# cpsw_CPSW3_08000000h register map
Vendor: Texas Instruments
Registers are 32-bit, read-write, reset 0x0 unless marked. A register's access mark holds for its fields unless they carry their own. Offsets are as the file gives them; [hi:lo] are bit positions; {n}, {i} and the like mark numbered series; 'fields as' and 'values as' point back to an identical list.

## cpsw3 (part 3 of 3)
0x22048 cpsw3_CPSW_NU_CPSW_NU_ETH_MAC_0_PN_IET_VERIFY_REG reset 0x1312D0 — Enet Port N IET VERIFY
  [23:0] MAC_VERIFY_CNT — IET MAC VERIFY COUNT
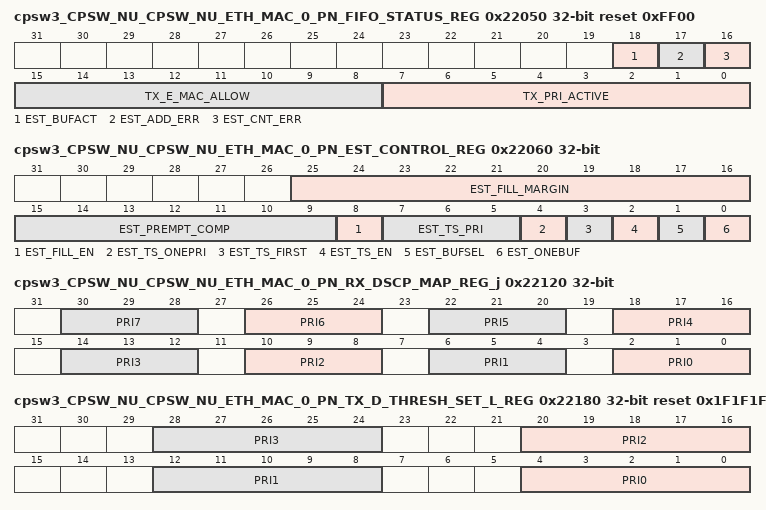
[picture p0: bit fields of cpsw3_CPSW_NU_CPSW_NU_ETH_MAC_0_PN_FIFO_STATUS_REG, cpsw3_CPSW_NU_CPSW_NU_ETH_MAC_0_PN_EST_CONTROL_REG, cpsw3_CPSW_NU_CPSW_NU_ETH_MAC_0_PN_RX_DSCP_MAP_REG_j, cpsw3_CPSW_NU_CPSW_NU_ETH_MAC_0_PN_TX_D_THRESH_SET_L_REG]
0x22050 cpsw3_CPSW_NU_CPSW_NU_ETH_MAC_0_PN_FIFO_STATUS_REG ro reset 0xFF00 — Enet Port N FIFO STATUS
  [18] EST_BUFACT — Transmit FIFO EST Buffer Active
  [17] EST_ADD_ERR — Transmit FIFO EST Address Error
  [16] EST_CNT_ERR — Transmit FIFO EST Count Error
  [15:8] TX_E_MAC_ALLOW — Transmit FIFO Express Queue Priority Allow
  [7:0] TX_PRI_ACTIVE — Transmit FIFO Priority Active
0x22060 cpsw3_CPSW_NU_CPSW_NU_ETH_MAC_0_PN_EST_CONTROL_REG — Enet Port N EST CONTROL
  [25:16] EST_FILL_MARGIN — Transmit FIFO EST Fill Margin
  [15:9] EST_PREMPT_COMP — Transmit FIFO EST Prempt Comparison Value to Clear wire
  [8] EST_FILL_EN — Transmit FIFO EST Fill Enable
  [7:5] EST_TS_PRI — Transmit FIFO EST TimeStamp Priority
  [4] EST_TS_ONEPRI — Transmit FIFO EST TimeStamp One Priority
  [3] EST_TS_FIRST — Transmit FIFO EST TimeStamp First Express Packet
  [2] EST_TS_EN — Transmit FIFO EST TimeStamp Enable
  [1] EST_BUFSEL — Transmit FIFO EST Buffer Select
  [0] EST_ONEBUF — Transmit FIFO EST One Buffer
0x22120 cpsw3_CPSW_NU_CPSW_NU_ETH_MAC_0_PN_RX_DSCP_MAP_REG_j — Enet Port N Receive IPV4/IPV6 DSCP Map M
  [4n+2:4n] PRI{n} (n=0..7) — A DSCP IPV4/V6 packet TOS of N*8+{n} is mapped to this received priority
0x22140 cpsw3_CPSW_NU_CPSW_NU_ETH_MAC_0_PN_PRI_CIR_REG_j — Enet Port N Rx Priority P Committed Information Rate Value
  [27:0] PRI_CIR — Priority N committed information rate
0x22160 cpsw3_CPSW_NU_CPSW_NU_ETH_MAC_0_PN_PRI_EIR_REG_j — Enet Port N Rx Priority P Excess Informatoin Rate Value
  [27:0] PRI_EIR — Priority N Excess Information Rate count
0x22180 cpsw3_CPSW_NU_CPSW_NU_ETH_MAC_0_PN_TX_D_THRESH_SET_L_REG reset 0x1F1F1F1F — Enet Port N Tx PFC Destination Threshold Set Low
  [8n+4:8n] PRI{n} (n=0..3) — Port Priority Based Flow Control Threshold Set Value for Priority {n}
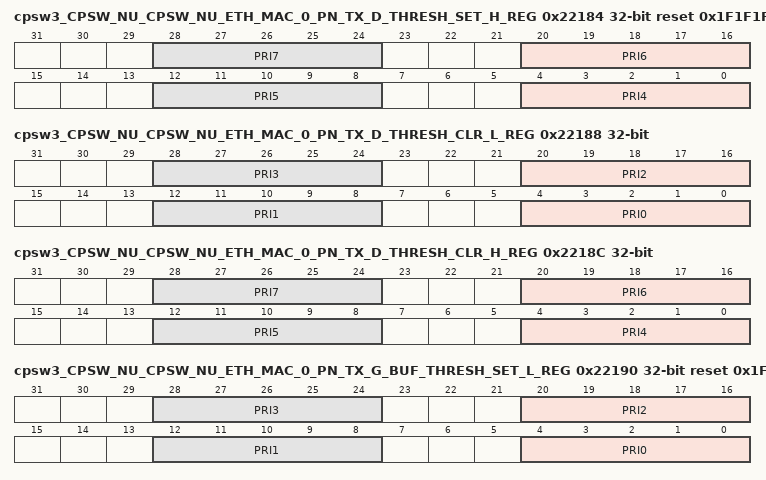
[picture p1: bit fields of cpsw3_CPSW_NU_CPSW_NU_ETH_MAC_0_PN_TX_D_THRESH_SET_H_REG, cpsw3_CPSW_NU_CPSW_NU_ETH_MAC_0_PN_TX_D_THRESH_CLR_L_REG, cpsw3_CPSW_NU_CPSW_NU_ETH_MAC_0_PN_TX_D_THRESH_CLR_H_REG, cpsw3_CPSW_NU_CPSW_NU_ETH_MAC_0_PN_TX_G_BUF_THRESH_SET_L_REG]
0x22184 cpsw3_CPSW_NU_CPSW_NU_ETH_MAC_0_PN_TX_D_THRESH_SET_H_REG reset 0x1F1F1F1F — Enet Port N Tx PFC Destination Threshold Set High
  [8n-28:8n-32] PRI{n} (n=4..7) — Port Priority Based Flow Control Threshold Set Value for Priority {n}
0x22188 cpsw3_CPSW_NU_CPSW_NU_ETH_MAC_0_PN_TX_D_THRESH_CLR_L_REG — Enet Port N Tx PFC Destination Threshold Clr Low
  [8n+4:8n] PRI{n} (n=0..3) — Port Priority Based Flow Control Threshold Clear Value for Priority {n}
0x2218C cpsw3_CPSW_NU_CPSW_NU_ETH_MAC_0_PN_TX_D_THRESH_CLR_H_REG — Enet Port N Tx PFC Destination Threshold Clr High
  [8n-28:8n-32] PRI{n} (n=4..7) — Port Priority Based Flow Control Threshold Clear Value for Priority {n}
0x22190 cpsw3_CPSW_NU_CPSW_NU_ETH_MAC_0_PN_TX_G_BUF_THRESH_SET_L_REG reset 0x1F1F1F1F — Enet Port N Tx PFC Global Buffer Threshold Set Low
  fields as cpsw3_CPSW_NU_CPSW_NU_ETH_MAC_0_PN_TX_D_THRESH_SET_L_REG
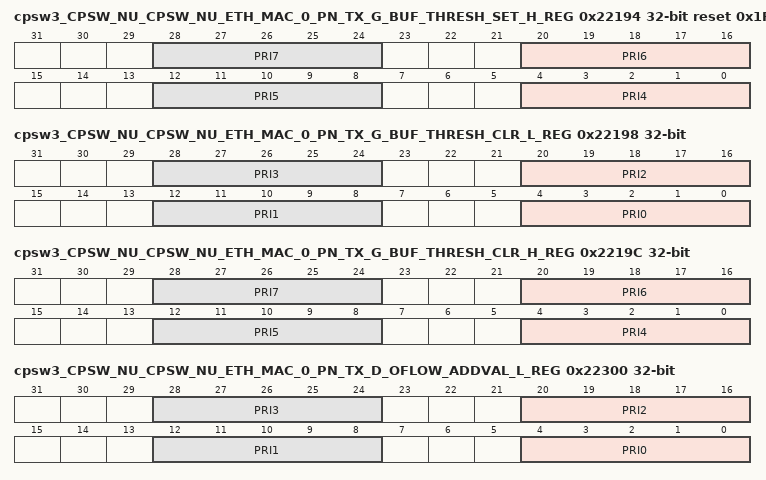
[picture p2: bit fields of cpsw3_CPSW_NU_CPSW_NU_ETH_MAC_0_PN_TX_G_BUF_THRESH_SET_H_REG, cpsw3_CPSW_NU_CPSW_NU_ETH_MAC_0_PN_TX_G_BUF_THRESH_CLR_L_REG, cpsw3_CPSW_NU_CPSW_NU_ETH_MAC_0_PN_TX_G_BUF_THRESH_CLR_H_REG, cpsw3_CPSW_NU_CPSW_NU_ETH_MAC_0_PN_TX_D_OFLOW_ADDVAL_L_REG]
0x22194 cpsw3_CPSW_NU_CPSW_NU_ETH_MAC_0_PN_TX_G_BUF_THRESH_SET_H_REG reset 0x1F1F1F1F — Enet Port N Tx PFC Global Buffer Threshold Set High
  fields as cpsw3_CPSW_NU_CPSW_NU_ETH_MAC_0_PN_TX_D_THRESH_SET_H_REG
0x22198 cpsw3_CPSW_NU_CPSW_NU_ETH_MAC_0_PN_TX_G_BUF_THRESH_CLR_L_REG — Enet Port N Tx PFC Global Buffer Threshold Clr Low
  fields as cpsw3_CPSW_NU_CPSW_NU_ETH_MAC_0_PN_TX_D_THRESH_CLR_L_REG
0x2219C cpsw3_CPSW_NU_CPSW_NU_ETH_MAC_0_PN_TX_G_BUF_THRESH_CLR_H_REG — Enet Port N Tx PFC Global Buffer Threshold Clr High
  fields as cpsw3_CPSW_NU_CPSW_NU_ETH_MAC_0_PN_TX_D_THRESH_CLR_H_REG
0x22300 cpsw3_CPSW_NU_CPSW_NU_ETH_MAC_0_PN_TX_D_OFLOW_ADDVAL_L_REG — Enet Port N Tx Destination Out Flow Add Values Low
  [8n+4:8n] PRI{n} (n=0..3) — Port PFC Destination Based Out Flow Add Value for Priority {n}
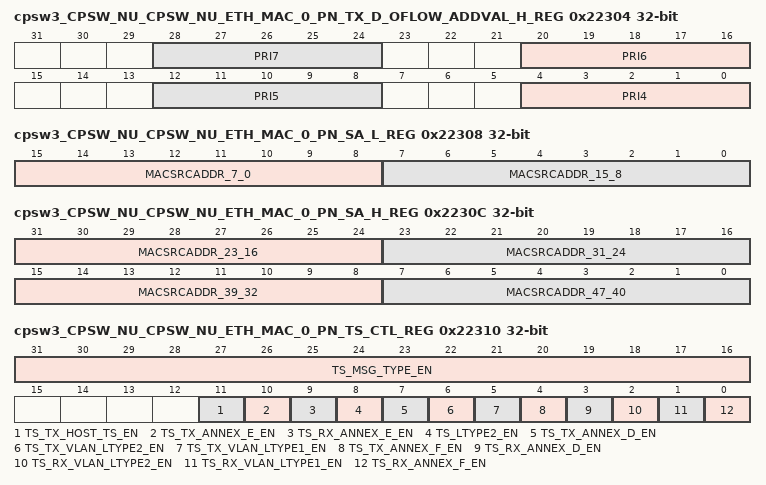
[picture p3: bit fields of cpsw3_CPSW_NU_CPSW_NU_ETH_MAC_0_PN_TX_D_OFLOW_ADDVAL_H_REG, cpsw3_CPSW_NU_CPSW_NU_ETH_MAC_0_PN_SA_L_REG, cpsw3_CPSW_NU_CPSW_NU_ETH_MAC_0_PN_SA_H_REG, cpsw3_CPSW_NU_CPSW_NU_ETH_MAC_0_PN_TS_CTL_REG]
0x22304 cpsw3_CPSW_NU_CPSW_NU_ETH_MAC_0_PN_TX_D_OFLOW_ADDVAL_H_REG — Enet Port N Tx Destination Out Flow Add Values High
  [8n-28:8n-32] PRI{n} (n=4..7) — Port PFC Destination Based Out Flow Add Value for Priority {n}
0x22308 cpsw3_CPSW_NU_CPSW_NU_ETH_MAC_0_PN_SA_L_REG — Enet Port N Tx Pause Frame Source Address Low
  [15:8] MACSRCADDR_7_0 — Source Address Lower 8 bits
  [7:0] MACSRCADDR_15_8 — Source Address bits 15:8
0x2230C cpsw3_CPSW_NU_CPSW_NU_ETH_MAC_0_PN_SA_H_REG — Enet Port N Tx Pause Frame Source Address High
  [31:24] MACSRCADDR_23_16 — Source Address bits 23:16
  [23:16] MACSRCADDR_31_24 — Source Address bits 31:24
  [15:8] MACSRCADDR_39_32 — Source Address bits 39:32
  [7:0] MACSRCADDR_47_40 — Source Address bits 47:40
0x22310 cpsw3_CPSW_NU_CPSW_NU_ETH_MAC_0_PN_TS_CTL_REG — Enet Port N Time Sync Control
  [31:16] TS_MSG_TYPE_EN — Time Sync Message Type Enable
  [11] TS_TX_HOST_TS_EN — Time Sync Transmit Host Time Stamp Enable
  [10] TS_TX_ANNEX_E_EN — Time Synce Transmit Annex E Enable
  [9] TS_RX_ANNEX_E_EN — Time Synce Receive Annex E Enable
  [8] TS_LTYPE2_EN — Time Sync LTYPE 2 enable transmit and receive
  [7] TS_TX_ANNEX_D_EN — Time Synce Transmit Annex D Enable
  [6] TS_TX_VLAN_LTYPE2_EN — Time Sync Transmit VLAN LTYPE 2 enable
  [5] TS_TX_VLAN_LTYPE1_EN — Time Sync Transmit VLAN LTYPE 1 enable
  [4] TS_TX_ANNEX_F_EN — Time Synce Transmit Annex F Enable
  [3] TS_RX_ANNEX_D_EN — Time Synce Receive Annex D Enable
  [2] TS_RX_VLAN_LTYPE2_EN — Time Sync Receive VLAN LTYPE 2 enable
  [1] TS_RX_VLAN_LTYPE1_EN — Time Sync Receive VLAN LTYPE 1 enable
  [0] TS_RX_ANNEX_F_EN — Time Synce Receive Annex F Enable
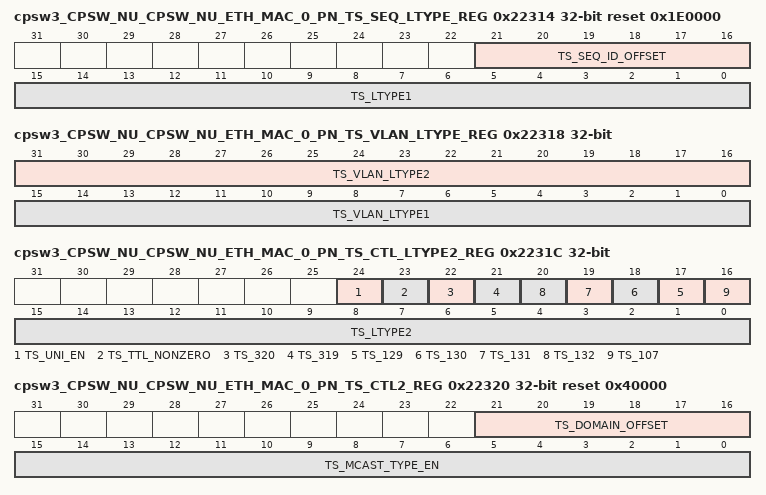
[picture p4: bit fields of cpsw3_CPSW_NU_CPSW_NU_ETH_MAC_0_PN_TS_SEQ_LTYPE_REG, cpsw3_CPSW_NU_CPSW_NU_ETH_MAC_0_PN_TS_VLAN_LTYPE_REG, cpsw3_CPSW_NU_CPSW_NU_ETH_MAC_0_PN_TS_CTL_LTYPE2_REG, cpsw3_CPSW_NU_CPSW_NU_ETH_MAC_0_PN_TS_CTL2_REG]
0x22314 cpsw3_CPSW_NU_CPSW_NU_ETH_MAC_0_PN_TS_SEQ_LTYPE_REG reset 0x1E0000 — Enet Port N Time Sync LTYPE (and SEQ_ID_OFFSET)
  [21:16] TS_SEQ_ID_OFFSET — Time Sync Sequence ID Offset
  [15:0] TS_LTYPE1 — Time Sync LTYPE1
0x22318 cpsw3_CPSW_NU_CPSW_NU_ETH_MAC_0_PN_TS_VLAN_LTYPE_REG — Enet Port N Time Sync VLAN2 and VLAN2
  [31:16] TS_VLAN_LTYPE2 — Time Sync VLAN LTYPE2
  [15:0] TS_VLAN_LTYPE1 — Time Sync VLAN LTYPE1
0x2231C cpsw3_CPSW_NU_CPSW_NU_ETH_MAC_0_PN_TS_CTL_LTYPE2_REG — Enet Port N Time Sync Control and LTYPE 2
  [24] TS_UNI_EN — Time Sync Unicast Enable
  [23] TS_TTL_NONZERO — Time Sync Time to Live Non-zero Enable
  [22] TS_320 — Time Sync Destination IP Address 320 Enable
  [21] TS_319 — Time Sync Destination IP Address 319 Enable
  [n-112] TS_{n} (n=129..132) — Time Sync Destination IP Address {n} Enable
  [16] TS_107 — Time Sync Destination IP Address 107 Enable
  [15:0] TS_LTYPE2 — Time Sync LTYPE2
0x22320 cpsw3_CPSW_NU_CPSW_NU_ETH_MAC_0_PN_TS_CTL2_REG reset 0x40000 — Enet Port N Time Sync Control 2
  [21:16] TS_DOMAIN_OFFSET — Time Sync Domain Offset
  [15:0] TS_MCAST_TYPE_EN — Time Sync Multicast Destination Address Type Enable
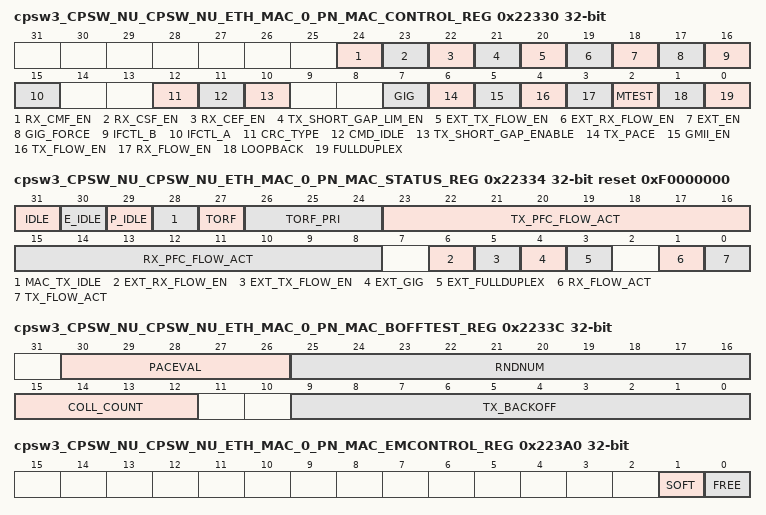
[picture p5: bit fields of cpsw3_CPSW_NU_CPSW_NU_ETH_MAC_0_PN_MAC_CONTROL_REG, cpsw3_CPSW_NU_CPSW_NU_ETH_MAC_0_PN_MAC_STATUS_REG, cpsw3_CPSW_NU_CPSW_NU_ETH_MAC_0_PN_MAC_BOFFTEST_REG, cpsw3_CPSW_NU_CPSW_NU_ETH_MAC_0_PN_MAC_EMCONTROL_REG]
0x22330 cpsw3_CPSW_NU_CPSW_NU_ETH_MAC_0_PN_MAC_CONTROL_REG — Enet Port N Mac Control
  [24] RX_CMF_EN — RX Copy MAC Control Frames Enable
  [23] RX_CSF_EN — RX Copy Short Frames Enable
  [22] RX_CEF_EN — RX Copy Error Frames Enable
  [21] TX_SHORT_GAP_LIM_EN — Transmit Short Gap Limit Enable
  [20] EXT_TX_FLOW_EN — External Transmit Flow Control Enable
  [19] EXT_RX_FLOW_EN — External Receive Flow Control Enable
  [18] EXT_EN — External Enable
  [17] GIG_FORCE — Gigabit Mode Force
  [16] IFCTL_B — Interface Control B
  [15] IFCTL_A — Interface Control A
  [12] CRC_TYPE — Port CRC Type
  [11] CMD_IDLE — Command Idle
  [10] TX_SHORT_GAP_ENABLE — Transmit Short Gap Enable
  [7] GIG — Gigabit Mode
  [6] TX_PACE — Transmit Pacing Enable
  [5] GMII_EN — GMII Enable
  [4] TX_FLOW_EN — Transmit Flow Control Enable
  [3] RX_FLOW_EN — Receive Flow Control Enable
  [2] MTEST — Manufacturing Test Mode
  [1] LOOPBACK — Loop Back Mode
  [0] FULLDUPLEX — Full Duplex mode
0x22334 cpsw3_CPSW_NU_CPSW_NU_ETH_MAC_0_PN_MAC_STATUS_REG ro reset 0xF0000000 — Enet Port N Mac Status
  [31] IDLE — cpxmac_sl IDLE
  [30] E_IDLE — Express cpxmac_sl IDLE
  [29] P_IDLE — Prempt cpxmac_sl IDLE
  [28] MAC_TX_IDLE — Prempt and Express cpxmac_sl Transmit IDLE
  [27] TORF — Top of receive FIFO flow control trigger occurred. This bit is write one to clear.
  [26:24] TORF_PRI — The lowest priority that caused top of receive FIFO flow control trigger since the last write to clear. This field is write 0x7 to clear.
  [23:16] TX_PFC_FLOW_ACT — Transmit Priority Based Flow Control Active (priority 7 down to 0)
  [15:8] RX_PFC_FLOW_ACT — Receive Priority Based Flow Control Active (priority 7 down to 0)
  [6] EXT_RX_FLOW_EN — External Transmit Flow Control Enable
  [5] EXT_TX_FLOW_EN — External Receive Flow Control Enable
  [4] EXT_GIG — External GIG mode
  [3] EXT_FULLDUPLEX — External Fullduplex
  [1] RX_FLOW_ACT — Receive Flow Control Active
  [0] TX_FLOW_ACT — Transmit Flow Control Active
0x22338 cpsw3_CPSW_NU_CPSW_NU_ETH_MAC_0_PN_MAC_SOFT_RESET_REG — Enet Port N Mac Soft Reset
  [0] SOFT_RESET — Software reset
0x2233C cpsw3_CPSW_NU_CPSW_NU_ETH_MAC_0_PN_MAC_BOFFTEST_REG access per field — Enet Port N Mac Backoff Test
  [30:26] PACEVAL rw — Pacing Register Current Value
  [25:16] RNDNUM rw — Backoff Random Number Generator
  [15:12] COLL_COUNT ro — Collision Count
  [9:0] TX_BACKOFF ro — Backoff Count
0x22340 cpsw3_CPSW_NU_CPSW_NU_ETH_MAC_0_PN_MAC_RX_PAUSETIMER_REG — Enet Port N 802.3 Receive Pause Timer
  [15:0] RX_PAUSETIMER — RX Pause Timer Value
0x22350 cpsw3_CPSW_NU_CPSW_NU_ETH_MAC_0_PN_MAC_RXN_PAUSETIMER_REG_j — Enet Port N PFC Priority P Rx Pause Timer
  [15:0] RX_PAUSETIMER — RX Pause Timer Value
0x22370 cpsw3_CPSW_NU_CPSW_NU_ETH_MAC_0_PN_MAC_TX_PAUSETIMER_REG — Enet Port N 802.3 Tx Pause Timer
  [15:0] TX_PAUSETIMER — TX Pause Timer Value
0x22380 cpsw3_CPSW_NU_CPSW_NU_ETH_MAC_0_PN_MAC_TXN_PAUSETIMER_REG_j — Enet Port N PFC Priority P Tx Pause Timer
  [15:0] TX_PAUSETIMER — TX Pause Timer Value
0x223A0 cpsw3_CPSW_NU_CPSW_NU_ETH_MAC_0_PN_MAC_EMCONTROL_REG — Enet Port N Emulation Control
  [1] SOFT — Emulation Soft Bit
  [0] FREE — Emulation Free Bit
0x223A4 cpsw3_CPSW_NU_CPSW_NU_ETH_MAC_0_PN_MAC_TX_GAP_REG reset 0xC — Enet Port N Tx Inter Packet Gap
  [15:0] TX_GAP — Transmit Inter-Packet Gap
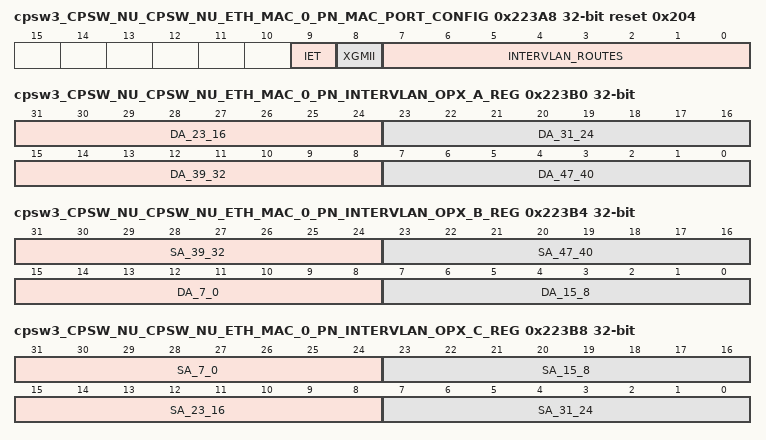
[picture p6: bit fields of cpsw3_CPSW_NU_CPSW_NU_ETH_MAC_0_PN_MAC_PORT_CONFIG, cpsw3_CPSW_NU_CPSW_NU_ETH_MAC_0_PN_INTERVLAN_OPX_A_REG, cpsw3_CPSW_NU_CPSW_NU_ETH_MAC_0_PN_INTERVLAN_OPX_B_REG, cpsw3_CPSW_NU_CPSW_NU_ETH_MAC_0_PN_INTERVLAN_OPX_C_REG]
0x223A8 cpsw3_CPSW_NU_CPSW_NU_ETH_MAC_0_PN_MAC_PORT_CONFIG ro reset 0x204 — Enet Port N Port Configuration
  [9] IET — IET support
  [8] XGMII — XGMII support
  [7:0] INTERVLAN_ROUTES — The number of InterVLAN routes
0x223AC cpsw3_CPSW_NU_CPSW_NU_ETH_MAC_0_PN_INTERVLAN_OPX_POINTER_REG — Enet Port N Tx Egress InterVLAN Operation Pointer
  [2:0] POINTER — InterVLAN location pointer: This field points to the InterVLAN location that will be read/written by accesses to Enet_Pn_InterVLANx_A/B.
0x223B0 cpsw3_CPSW_NU_CPSW_NU_ETH_MAC_0_PN_INTERVLAN_OPX_A_REG — Enet Port N Tx Egress InterVLAN A
  [31:24] DA_23_16 — Destination Address bits 23:16
  [23:16] DA_31_24 — Destination Address bits 31:24
  [15:8] DA_39_32 — Destination Address bits 39:32
  [7:0] DA_47_40 — Destination Address bits 47:40
0x223B4 cpsw3_CPSW_NU_CPSW_NU_ETH_MAC_0_PN_INTERVLAN_OPX_B_REG — Enet Port N Tx Egress InterVLAN B
  [31:24] SA_39_32 — Source Address bits 39:32
  [23:16] SA_47_40 — Source Address bits 47:40
  [15:8] DA_7_0 — Destination Address bits 7:0
  [7:0] DA_15_8 — Destination Address bits 15:8
0x223B8 cpsw3_CPSW_NU_CPSW_NU_ETH_MAC_0_PN_INTERVLAN_OPX_C_REG — Enet Port N Tx Egress InterVLAN C
  [31:24] SA_7_0 — Source Address bits 7:0
  [23:16] SA_15_8 — Source Address bits 15:8
  [15:8] SA_23_16 — Source Address bits 23:16
  [7:0] SA_31_24 — Source Address bits 31:24
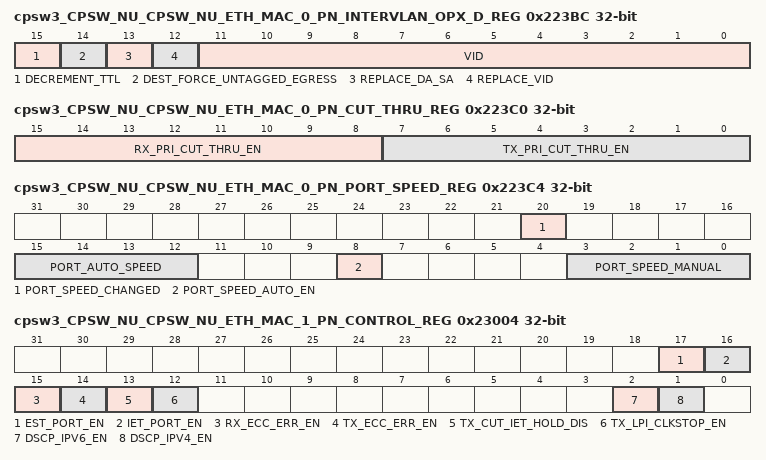
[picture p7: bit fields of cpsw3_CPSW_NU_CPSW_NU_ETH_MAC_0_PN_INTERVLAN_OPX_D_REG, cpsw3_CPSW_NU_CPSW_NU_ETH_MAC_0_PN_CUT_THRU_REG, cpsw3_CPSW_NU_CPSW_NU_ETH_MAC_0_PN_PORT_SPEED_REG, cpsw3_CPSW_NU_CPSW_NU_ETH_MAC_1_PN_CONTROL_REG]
0x223BC cpsw3_CPSW_NU_CPSW_NU_ETH_MAC_0_PN_INTERVLAN_OPX_D_REG — Enet Port N Tx Egress InterVLAN D
  [15] DECREMENT_TTL — Decrement Time To Live: When set, the Time To Live (TTL) field in the header is decremented.
  [14] DEST_FORCE_UNTAGGED_EGRESS — Destination VLAN Force Untagged Egress: When set, this bit indicates that the VLAN should be removed on egress for the routed packet.
  [13] REPLACE_DA_SA — Replace Destination Address and Source Address: When set this bit indicates that the routed packet destination address should be replaced by da[47:0] and the source address should be replaced by sa[47:0].
  [12] REPLACE_VID — Replace VLAN ID: When set this bit indicates that the VLAN ID should be replaced for the routed packet.
  [11:0] VID — VLAN ID
0x223C0 cpsw3_CPSW_NU_CPSW_NU_ETH_MAC_0_PN_CUT_THRU_REG — Enet Port N Cut Thru Priority Enable
  [15:8] RX_PRI_CUT_THRU_EN — Receive Cut Thru Priority Enable
  [7:0] TX_PRI_CUT_THRU_EN — Transmit Cut Thru Priority Enable
0x223C4 cpsw3_CPSW_NU_CPSW_NU_ETH_MAC_0_PN_PORT_SPEED_REG access per field — Enet Port Speed
  [20] PORT_SPEED_CHANGED ro
  [15:12] PORT_AUTO_SPEED ro — Detected Auto Speed
  [8] PORT_SPEED_AUTO_EN rw — Automatic Port Speed Enable
  [3:0] PORT_SPEED_MANUAL rw — Manual Port Speed
0x23000 cpsw3_CPSW_NU_CPSW_NU_ETH_MAC_1 access not given reset not defined
0x23000 cpsw3_CPSW_NU_CPSW_NU_ETH_MAC_1_PN_RESERVED_REG ro — Reserved
0x23004 cpsw3_CPSW_NU_CPSW_NU_ETH_MAC_1_PN_CONTROL_REG — Enet Port N Control
  [17] EST_PORT_EN — EST Port Enable
  [16] IET_PORT_EN — IET Port Enable
  [15] RX_ECC_ERR_EN — Port 0 Receive ECC Error Enable
  [14] TX_ECC_ERR_EN — Port 0 Transmit ECC Error Enable
  [13] TX_CUT_IET_HOLD_DIS — Cut-Thru IET Prempt Hold Disable
  [12] TX_LPI_CLKSTOP_EN — Transmit LPI clockstop enable
  [2] DSCP_IPV6_EN — IPv6 DSCP enable
  [1] DSCP_IPV4_EN — IPv4 DSCP enable
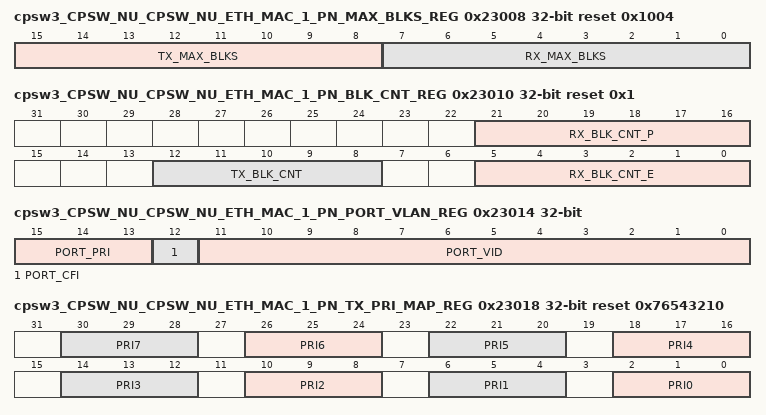
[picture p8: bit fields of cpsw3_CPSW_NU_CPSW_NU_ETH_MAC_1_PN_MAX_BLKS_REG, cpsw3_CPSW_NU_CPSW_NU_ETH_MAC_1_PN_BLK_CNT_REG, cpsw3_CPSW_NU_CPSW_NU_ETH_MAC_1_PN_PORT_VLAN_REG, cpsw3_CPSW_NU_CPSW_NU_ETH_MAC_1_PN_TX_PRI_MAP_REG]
0x23008 cpsw3_CPSW_NU_CPSW_NU_ETH_MAC_1_PN_MAX_BLKS_REG reset 0x1004 — Enet Port N FIFO Max Blocks
  [15:8] TX_MAX_BLKS — Transmit FIFO maximum blocks
  [7:0] RX_MAX_BLKS — Receive FIFO maximum blocks
0x23010 cpsw3_CPSW_NU_CPSW_NU_ETH_MAC_1_PN_BLK_CNT_REG ro reset 0x1 — Enet Port N FIFO Block Usage Count
  [21:16] RX_BLK_CNT_P — Receive Prempt Queue Block Count Usage
  [12:8] TX_BLK_CNT — Transmit Block Count Usage
  [5:0] RX_BLK_CNT_E — Receive Block Count Usage
0x23014 cpsw3_CPSW_NU_CPSW_NU_ETH_MAC_1_PN_PORT_VLAN_REG — Enet Port N VLAN
  [15:13] PORT_PRI — Port VLAN Priority
  [12] PORT_CFI — Port CFI bit
  [11:0] PORT_VID — Port VLAN ID
0x23018 cpsw3_CPSW_NU_CPSW_NU_ETH_MAC_1_PN_TX_PRI_MAP_REG reset 0x76543210 — Enet Port N Tx Header Pri to Switch Pri Mapping
  [4n+2:4n] PRI{n} (n=0..7) — Priority {n}
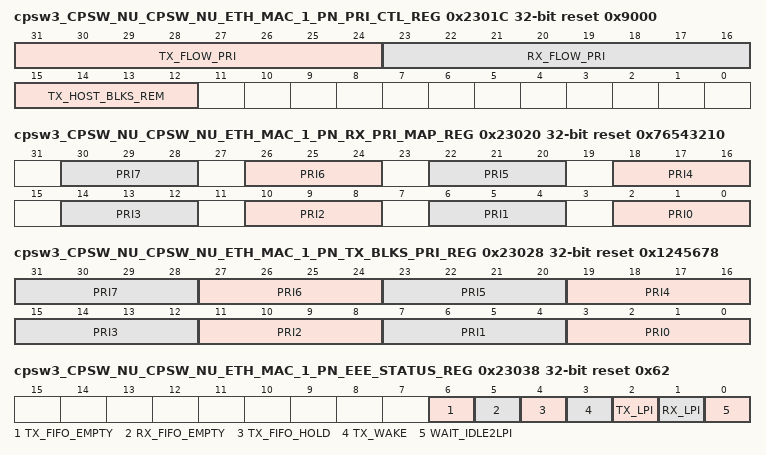
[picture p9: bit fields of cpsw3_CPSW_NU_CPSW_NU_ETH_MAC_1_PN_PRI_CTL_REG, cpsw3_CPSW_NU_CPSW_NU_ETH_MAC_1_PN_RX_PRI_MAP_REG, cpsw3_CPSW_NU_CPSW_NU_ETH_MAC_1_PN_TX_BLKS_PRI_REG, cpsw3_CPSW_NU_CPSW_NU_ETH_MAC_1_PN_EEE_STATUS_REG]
0x2301C cpsw3_CPSW_NU_CPSW_NU_ETH_MAC_1_PN_PRI_CTL_REG reset 0x9000 — Enet Port N Priority Control
  [31:24] TX_FLOW_PRI — Transmit Priority Based Flow Control Enable (per priority)
  [23:16] RX_FLOW_PRI — Receive Priority Based Flow Control Enable (per priority)
  [15:12] TX_HOST_BLKS_REM — Transmit FIFO Blocks that must be free before a non rate-limited CPPI Port 0 receive thread can begin sending a packet
0x23020 cpsw3_CPSW_NU_CPSW_NU_ETH_MAC_1_PN_RX_PRI_MAP_REG reset 0x76543210 — Enet Port N RX Pkt Pri to Header Pri Map
  [4n+2:4n] PRI{n} (n=0..7) — Priority {n}
0x23024 cpsw3_CPSW_NU_CPSW_NU_ETH_MAC_1_PN_RX_MAXLEN_REG reset 0x5EE — Enet Port N Receive Frame Max Length
  [13:0] RX_MAXLEN — Rx Maximum Frame Length
0x23028 cpsw3_CPSW_NU_CPSW_NU_ETH_MAC_1_PN_TX_BLKS_PRI_REG reset 0x1245678 — Enet Port N Transmit Block Sub Per Priority
  [4n+3:4n] PRI{n} (n=0..7) — Priority {n} Port Transmit Blocks
0x23030 cpsw3_CPSW_NU_CPSW_NU_ETH_MAC_1_PN_IDLE2LPI_REG — Enet Port N EEE Idle to LPI counter
  [23:0] COUNT — EEE Idle to LPI counter load value
0x23034 cpsw3_CPSW_NU_CPSW_NU_ETH_MAC_1_PN_LPI2WAKE_REG — Enet Port N EEE LPI to wake counter
  [23:0] COUNT — EEE LPI to wake counter load value
0x23038 cpsw3_CPSW_NU_CPSW_NU_ETH_MAC_1_PN_EEE_STATUS_REG ro reset 0x62 — Enet Port N EEE status
  [6] TX_FIFO_EMPTY — Transmit FIFO (switch egress) is empty - contains no packets
  [5] RX_FIFO_EMPTY — Receive FIFO (switch ingress) is empty - contains no packets
  [4] TX_FIFO_HOLD — Transmit FIFO hold - asserted in the LPI state and during the LPI2WAKE count time
  [3] TX_WAKE — Transmit wakeup - asserted in the transmit LPI2WAKE count time
  [2] TX_LPI — Transmit LPI state - asserted when the port 0 transmit is in the LPI state
  [1] RX_LPI — Receive LPI state - asserted when the port 0 receive is in the LPI state
  [0] WAIT_IDLE2LPI — CPPI port 0 wait idle to LPI - asserted when port 0 is counting the IDLE2LPI time
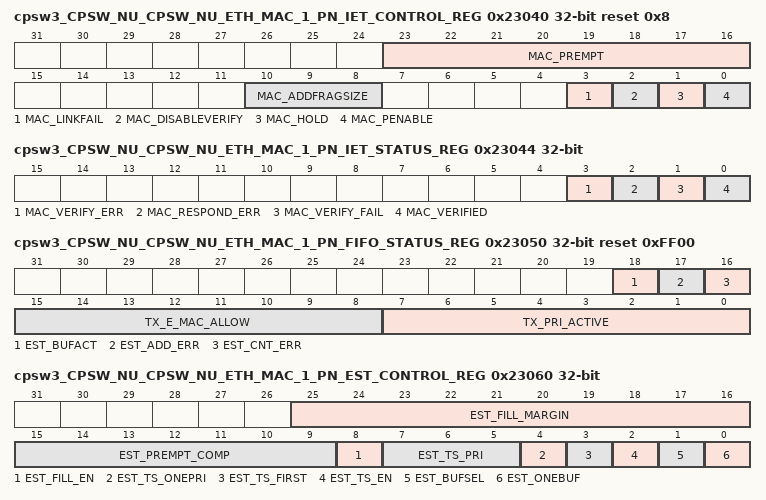
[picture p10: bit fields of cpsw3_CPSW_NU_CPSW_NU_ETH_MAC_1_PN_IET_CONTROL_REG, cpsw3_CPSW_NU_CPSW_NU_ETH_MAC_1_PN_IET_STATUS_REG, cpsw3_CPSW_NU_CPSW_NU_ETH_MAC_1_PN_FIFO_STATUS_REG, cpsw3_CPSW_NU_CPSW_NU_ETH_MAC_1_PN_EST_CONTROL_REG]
0x23040 cpsw3_CPSW_NU_CPSW_NU_ETH_MAC_1_PN_IET_CONTROL_REG reset 0x8 — Enet Port N IET Control
  [23:16] MAC_PREMPT — IET MAC Fragment Size
  [10:8] MAC_ADDFRAGSIZE — IET MAC Fragment Size
  [3] MAC_LINKFAIL — IET MAC LINK Fail Reset
  [2] MAC_DISABLEVERIFY — IET MAC Disable Verify
  [1] MAC_HOLD — IET MAC HOLD
  [0] MAC_PENABLE — IET MAC Penable
0x23044 cpsw3_CPSW_NU_CPSW_NU_ETH_MAC_1_PN_IET_STATUS_REG ro — Enet Port N IET Status
  [3] MAC_VERIFY_ERR — IET MAC VERIFY ERROR
  [2] MAC_RESPOND_ERR — IET MAC RESPONSE ERROR
  [1] MAC_VERIFY_FAIL — IET MAC VERIFY FAIL
  [0] MAC_VERIFIED — IET MAC VERIFIED
0x23048 cpsw3_CPSW_NU_CPSW_NU_ETH_MAC_1_PN_IET_VERIFY_REG reset 0x1312D0 — Enet Port N IET VERIFY
  [23:0] MAC_VERIFY_CNT — IET MAC VERIFY COUNT
0x23050 cpsw3_CPSW_NU_CPSW_NU_ETH_MAC_1_PN_FIFO_STATUS_REG ro reset 0xFF00 — Enet Port N FIFO STATUS
  fields as cpsw3_CPSW_NU_CPSW_NU_ETH_MAC_0_PN_FIFO_STATUS_REG
0x23060 cpsw3_CPSW_NU_CPSW_NU_ETH_MAC_1_PN_EST_CONTROL_REG — Enet Port N EST CONTROL
  fields as cpsw3_CPSW_NU_CPSW_NU_ETH_MAC_0_PN_EST_CONTROL_REG
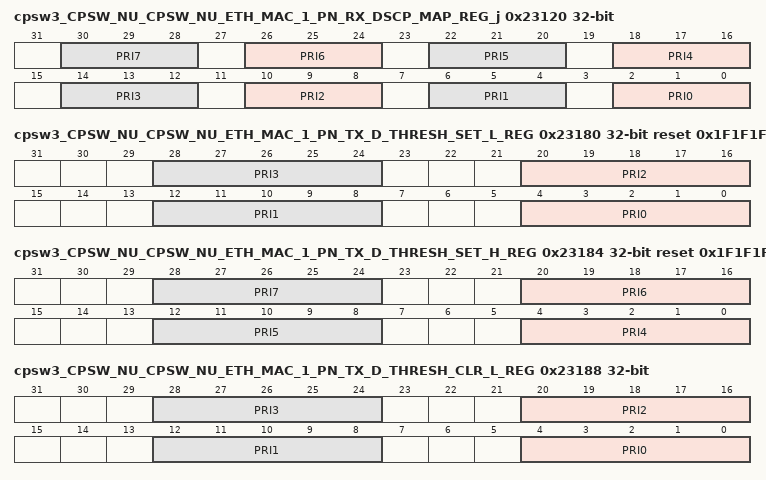
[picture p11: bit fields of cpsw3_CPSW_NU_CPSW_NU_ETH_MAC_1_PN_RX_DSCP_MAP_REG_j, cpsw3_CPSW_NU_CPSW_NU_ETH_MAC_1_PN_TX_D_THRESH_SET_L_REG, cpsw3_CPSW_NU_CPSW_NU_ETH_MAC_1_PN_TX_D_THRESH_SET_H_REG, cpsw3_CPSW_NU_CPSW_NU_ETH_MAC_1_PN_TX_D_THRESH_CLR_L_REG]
0x23120 cpsw3_CPSW_NU_CPSW_NU_ETH_MAC_1_PN_RX_DSCP_MAP_REG_j — Enet Port N Receive IPV4/IPV6 DSCP Map M
  fields as cpsw3_CPSW_NU_CPSW_NU_ETH_MAC_0_PN_RX_DSCP_MAP_REG_j
0x23140 cpsw3_CPSW_NU_CPSW_NU_ETH_MAC_1_PN_PRI_CIR_REG_j — Enet Port N Rx Priority P Committed Information Rate Value
  [27:0] PRI_CIR — Priority N committed information rate
0x23160 cpsw3_CPSW_NU_CPSW_NU_ETH_MAC_1_PN_PRI_EIR_REG_j — Enet Port N Rx Priority P Excess Informatoin Rate Value
  [27:0] PRI_EIR — Priority N Excess Information Rate count
0x23180 cpsw3_CPSW_NU_CPSW_NU_ETH_MAC_1_PN_TX_D_THRESH_SET_L_REG reset 0x1F1F1F1F — Enet Port N Tx PFC Destination Threshold Set Low
  fields as cpsw3_CPSW_NU_CPSW_NU_ETH_MAC_0_PN_TX_D_THRESH_SET_L_REG
0x23184 cpsw3_CPSW_NU_CPSW_NU_ETH_MAC_1_PN_TX_D_THRESH_SET_H_REG reset 0x1F1F1F1F — Enet Port N Tx PFC Destination Threshold Set High
  fields as cpsw3_CPSW_NU_CPSW_NU_ETH_MAC_0_PN_TX_D_THRESH_SET_H_REG
0x23188 cpsw3_CPSW_NU_CPSW_NU_ETH_MAC_1_PN_TX_D_THRESH_CLR_L_REG — Enet Port N Tx PFC Destination Threshold Clr Low
  fields as cpsw3_CPSW_NU_CPSW_NU_ETH_MAC_0_PN_TX_D_THRESH_CLR_L_REG
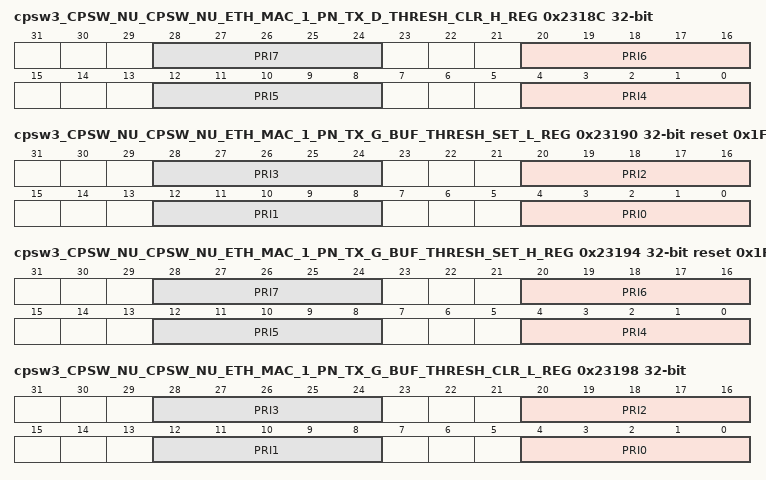
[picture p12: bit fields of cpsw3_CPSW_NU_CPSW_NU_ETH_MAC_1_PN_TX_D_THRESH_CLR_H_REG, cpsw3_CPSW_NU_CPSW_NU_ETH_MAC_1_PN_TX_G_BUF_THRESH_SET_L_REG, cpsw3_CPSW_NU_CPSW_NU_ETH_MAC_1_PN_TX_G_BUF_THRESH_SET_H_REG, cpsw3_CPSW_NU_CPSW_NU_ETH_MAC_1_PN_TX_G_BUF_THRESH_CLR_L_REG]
0x2318C cpsw3_CPSW_NU_CPSW_NU_ETH_MAC_1_PN_TX_D_THRESH_CLR_H_REG — Enet Port N Tx PFC Destination Threshold Clr High
  fields as cpsw3_CPSW_NU_CPSW_NU_ETH_MAC_0_PN_TX_D_THRESH_CLR_H_REG
0x23190 cpsw3_CPSW_NU_CPSW_NU_ETH_MAC_1_PN_TX_G_BUF_THRESH_SET_L_REG reset 0x1F1F1F1F — Enet Port N Tx PFC Global Buffer Threshold Set Low
  fields as cpsw3_CPSW_NU_CPSW_NU_ETH_MAC_0_PN_TX_D_THRESH_SET_L_REG
0x23194 cpsw3_CPSW_NU_CPSW_NU_ETH_MAC_1_PN_TX_G_BUF_THRESH_SET_H_REG reset 0x1F1F1F1F — Enet Port N Tx PFC Global Buffer Threshold Set High
  fields as cpsw3_CPSW_NU_CPSW_NU_ETH_MAC_0_PN_TX_D_THRESH_SET_H_REG
0x23198 cpsw3_CPSW_NU_CPSW_NU_ETH_MAC_1_PN_TX_G_BUF_THRESH_CLR_L_REG — Enet Port N Tx PFC Global Buffer Threshold Clr Low
  fields as cpsw3_CPSW_NU_CPSW_NU_ETH_MAC_0_PN_TX_D_THRESH_CLR_L_REG
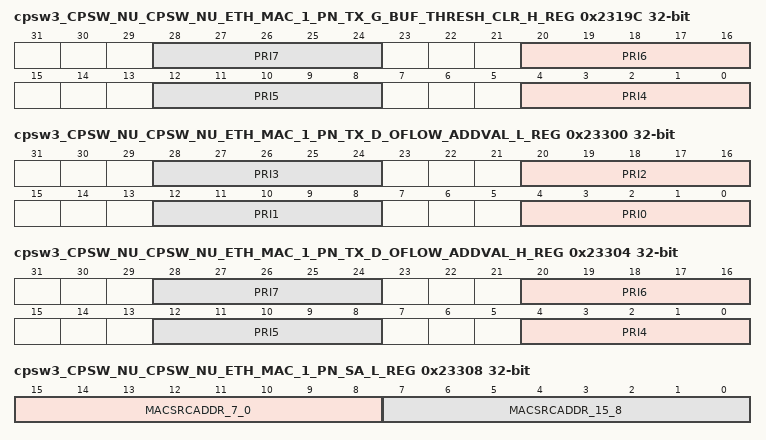
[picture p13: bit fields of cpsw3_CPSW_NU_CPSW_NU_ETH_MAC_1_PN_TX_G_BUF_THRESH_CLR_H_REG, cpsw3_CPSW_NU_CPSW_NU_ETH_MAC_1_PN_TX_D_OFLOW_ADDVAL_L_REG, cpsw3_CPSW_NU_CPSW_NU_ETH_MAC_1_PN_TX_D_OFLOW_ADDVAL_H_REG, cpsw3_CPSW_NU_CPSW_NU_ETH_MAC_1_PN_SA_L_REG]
0x2319C cpsw3_CPSW_NU_CPSW_NU_ETH_MAC_1_PN_TX_G_BUF_THRESH_CLR_H_REG — Enet Port N Tx PFC Global Buffer Threshold Clr High
  fields as cpsw3_CPSW_NU_CPSW_NU_ETH_MAC_0_PN_TX_D_THRESH_CLR_H_REG
0x23300 cpsw3_CPSW_NU_CPSW_NU_ETH_MAC_1_PN_TX_D_OFLOW_ADDVAL_L_REG — Enet Port N Tx Destination Out Flow Add Values Low
  fields as cpsw3_CPSW_NU_CPSW_NU_ETH_MAC_0_PN_TX_D_OFLOW_ADDVAL_L_REG
0x23304 cpsw3_CPSW_NU_CPSW_NU_ETH_MAC_1_PN_TX_D_OFLOW_ADDVAL_H_REG — Enet Port N Tx Destination Out Flow Add Values High
  fields as cpsw3_CPSW_NU_CPSW_NU_ETH_MAC_0_PN_TX_D_OFLOW_ADDVAL_H_REG
0x23308 cpsw3_CPSW_NU_CPSW_NU_ETH_MAC_1_PN_SA_L_REG — Enet Port N Tx Pause Frame Source Address Low
  fields as cpsw3_CPSW_NU_CPSW_NU_ETH_MAC_0_PN_SA_L_REG
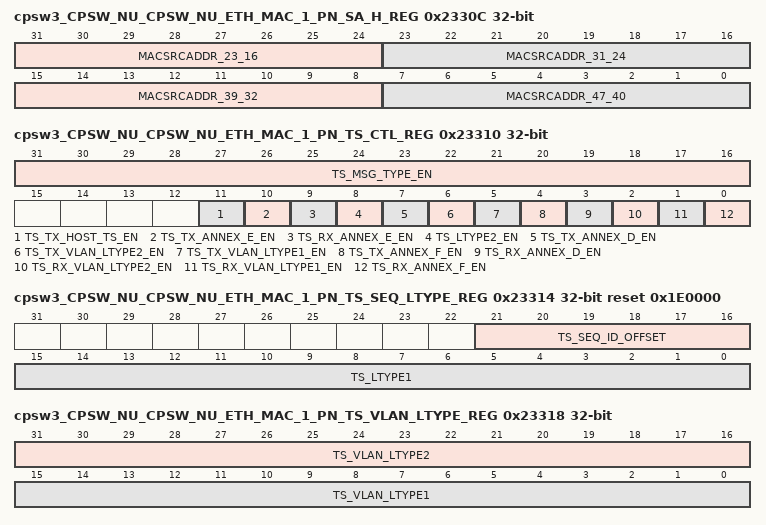
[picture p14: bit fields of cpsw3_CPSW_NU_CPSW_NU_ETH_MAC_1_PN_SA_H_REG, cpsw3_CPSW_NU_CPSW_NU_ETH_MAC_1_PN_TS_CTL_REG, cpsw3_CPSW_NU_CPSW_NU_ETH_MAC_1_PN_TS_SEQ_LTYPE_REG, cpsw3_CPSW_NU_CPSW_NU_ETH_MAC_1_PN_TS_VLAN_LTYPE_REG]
0x2330C cpsw3_CPSW_NU_CPSW_NU_ETH_MAC_1_PN_SA_H_REG — Enet Port N Tx Pause Frame Source Address High
  fields as cpsw3_CPSW_NU_CPSW_NU_ETH_MAC_0_PN_SA_H_REG
0x23310 cpsw3_CPSW_NU_CPSW_NU_ETH_MAC_1_PN_TS_CTL_REG — Enet Port N Time Sync Control
  fields as cpsw3_CPSW_NU_CPSW_NU_ETH_MAC_0_PN_TS_CTL_REG
0x23314 cpsw3_CPSW_NU_CPSW_NU_ETH_MAC_1_PN_TS_SEQ_LTYPE_REG reset 0x1E0000 — Enet Port N Time Sync LTYPE (and SEQ_ID_OFFSET)
  fields as cpsw3_CPSW_NU_CPSW_NU_ETH_MAC_0_PN_TS_SEQ_LTYPE_REG
0x23318 cpsw3_CPSW_NU_CPSW_NU_ETH_MAC_1_PN_TS_VLAN_LTYPE_REG — Enet Port N Time Sync VLAN2 and VLAN2
  fields as cpsw3_CPSW_NU_CPSW_NU_ETH_MAC_0_PN_TS_VLAN_LTYPE_REG
0x2331C cpsw3_CPSW_NU_CPSW_NU_ETH_MAC_1_PN_TS_CTL_LTYPE2_REG — Enet Port N Time Sync Control and LTYPE 2
  fields as cpsw3_CPSW_NU_CPSW_NU_ETH_MAC_0_PN_TS_CTL_LTYPE2_REG
0x23320 cpsw3_CPSW_NU_CPSW_NU_ETH_MAC_1_PN_TS_CTL2_REG reset 0x40000 — Enet Port N Time Sync Control 2
  fields as cpsw3_CPSW_NU_CPSW_NU_ETH_MAC_0_PN_TS_CTL2_REG
0x23330 cpsw3_CPSW_NU_CPSW_NU_ETH_MAC_1_PN_MAC_CONTROL_REG — Enet Port N Mac Control
  fields as cpsw3_CPSW_NU_CPSW_NU_ETH_MAC_0_PN_MAC_CONTROL_REG
0x23334 cpsw3_CPSW_NU_CPSW_NU_ETH_MAC_1_PN_MAC_STATUS_REG ro reset 0xF0000000 — Enet Port N Mac Status
  fields as cpsw3_CPSW_NU_CPSW_NU_ETH_MAC_0_PN_MAC_STATUS_REG
0x23338 cpsw3_CPSW_NU_CPSW_NU_ETH_MAC_1_PN_MAC_SOFT_RESET_REG — Enet Port N Mac Soft Reset
  [0] SOFT_RESET — Software reset
0x2333C cpsw3_CPSW_NU_CPSW_NU_ETH_MAC_1_PN_MAC_BOFFTEST_REG access per field — Enet Port N Mac Backoff Test
  fields as cpsw3_CPSW_NU_CPSW_NU_ETH_MAC_0_PN_MAC_BOFFTEST_REG
0x23340 cpsw3_CPSW_NU_CPSW_NU_ETH_MAC_1_PN_MAC_RX_PAUSETIMER_REG — Enet Port N 802.3 Receive Pause Timer
  [15:0] RX_PAUSETIMER — RX Pause Timer Value
0x23350 cpsw3_CPSW_NU_CPSW_NU_ETH_MAC_1_PN_MAC_RXN_PAUSETIMER_REG_j — Enet Port N PFC Priority P Rx Pause Timer
  [15:0] RX_PAUSETIMER — RX Pause Timer Value
0x23370 cpsw3_CPSW_NU_CPSW_NU_ETH_MAC_1_PN_MAC_TX_PAUSETIMER_REG — Enet Port N 802.3 Tx Pause Timer
  [15:0] TX_PAUSETIMER — TX Pause Timer Value
0x23380 cpsw3_CPSW_NU_CPSW_NU_ETH_MAC_1_PN_MAC_TXN_PAUSETIMER_REG_j — Enet Port N PFC Priority P Tx Pause Timer
  [15:0] TX_PAUSETIMER — TX Pause Timer Value
0x233A0 cpsw3_CPSW_NU_CPSW_NU_ETH_MAC_1_PN_MAC_EMCONTROL_REG — Enet Port N Emulation Control
  [1] SOFT — Emulation Soft Bit
  [0] FREE — Emulation Free Bit
0x233A4 cpsw3_CPSW_NU_CPSW_NU_ETH_MAC_1_PN_MAC_TX_GAP_REG reset 0xC — Enet Port N Tx Inter Packet Gap
  [15:0] TX_GAP — Transmit Inter-Packet Gap
0x233A8 cpsw3_CPSW_NU_CPSW_NU_ETH_MAC_1_PN_MAC_PORT_CONFIG ro reset 0x204 — Enet Port N Port Configuration
  fields as cpsw3_CPSW_NU_CPSW_NU_ETH_MAC_0_PN_MAC_PORT_CONFIG
0x233AC cpsw3_CPSW_NU_CPSW_NU_ETH_MAC_1_PN_INTERVLAN_OPX_POINTER_REG — Enet Port N Tx Egress InterVLAN Operation Pointer
  fields as cpsw3_CPSW_NU_CPSW_NU_ETH_MAC_0_PN_INTERVLAN_OPX_POINTER_REG
0x233B0 cpsw3_CPSW_NU_CPSW_NU_ETH_MAC_1_PN_INTERVLAN_OPX_A_REG — Enet Port N Tx Egress InterVLAN A
  fields as cpsw3_CPSW_NU_CPSW_NU_ETH_MAC_0_PN_INTERVLAN_OPX_A_REG
0x233B4 cpsw3_CPSW_NU_CPSW_NU_ETH_MAC_1_PN_INTERVLAN_OPX_B_REG — Enet Port N Tx Egress InterVLAN B
  fields as cpsw3_CPSW_NU_CPSW_NU_ETH_MAC_0_PN_INTERVLAN_OPX_B_REG
0x233B8 cpsw3_CPSW_NU_CPSW_NU_ETH_MAC_1_PN_INTERVLAN_OPX_C_REG — Enet Port N Tx Egress InterVLAN C
  fields as cpsw3_CPSW_NU_CPSW_NU_ETH_MAC_0_PN_INTERVLAN_OPX_C_REG
0x233BC cpsw3_CPSW_NU_CPSW_NU_ETH_MAC_1_PN_INTERVLAN_OPX_D_REG — Enet Port N Tx Egress InterVLAN D
  fields as cpsw3_CPSW_NU_CPSW_NU_ETH_MAC_0_PN_INTERVLAN_OPX_D_REG
0x233C0 cpsw3_CPSW_NU_CPSW_NU_ETH_MAC_1_PN_CUT_THRU_REG — Enet Port N Cut Thru Priority Enable
  fields as cpsw3_CPSW_NU_CPSW_NU_ETH_MAC_0_PN_CUT_THRU_REG
0x233C4 cpsw3_CPSW_NU_CPSW_NU_ETH_MAC_1_PN_PORT_SPEED_REG access per field — Enet Port Speed
  fields as cpsw3_CPSW_NU_CPSW_NU_ETH_MAC_0_PN_PORT_SPEED_REG
0x32000 cpsw3_CPSW_NU_CPSW_NU_EST access not given reset not defined
0x32000 cpsw3_CPSW_NU_CPSW_NU_EST_FETCH_LOC_j — The Revision Register contains the ID and revision information.
  [21:0] LOC — RAM Location
0x3A000 cpsw3_CPSW_NU_CPSW_NU_STAT_RXGOODFRAMES_k — Total number of good frames received
  [31:0] COUNT
0x3A004 cpsw3_CPSW_NU_CPSW_NU_STAT_RXBROADCASTFRAMES_k — Total number of good broadcast frames received
  [31:0] COUNT
0x3A008 cpsw3_CPSW_NU_CPSW_NU_STAT_RXMULTICASTFRAMES_k — Total number of good multicast frames received
  [31:0] COUNT
0x3A00C cpsw3_CPSW_NU_CPSW_NU_STAT_RXPAUSEFRAMES_k — Total number of pause frames received
  [31:0] COUNT
0x3A010 cpsw3_CPSW_NU_CPSW_NU_STAT_RXCRCERRORS_k — Total number of CRC errors frames received
  [31:0] COUNT
0x3A014 cpsw3_CPSW_NU_CPSW_NU_STAT_RXALIGNCODEERRORS_k — Total number of alignment/code errors received
  [31:0] COUNT
0x3A018 cpsw3_CPSW_NU_CPSW_NU_STAT_RXOVERSIZEDFRAMES_k — Total number of oversized frames received
  [31:0] COUNT
0x3A01C cpsw3_CPSW_NU_CPSW_NU_STAT_RXJABBERFRAMES_k — Total number of jabber frames received
  [31:0] COUNT
0x3A020 cpsw3_CPSW_NU_CPSW_NU_STAT_RXUNDERSIZEDFRAMES_k — Total number of undersized frames received
  [31:0] COUNT
0x3A024 cpsw3_CPSW_NU_CPSW_NU_STAT_RXFRAGMENTS_k — Total number of fragmented frames received
  [31:0] COUNT
0x3A028 cpsw3_CPSW_NU_CPSW_NU_STAT_ALE_DROP_k — Total number of frames dropped by the ALE
  [31:0] COUNT
0x3A02C cpsw3_CPSW_NU_CPSW_NU_STAT_ALE_OVERRUN_DROP_k — Total number of overrun frames dropped by the ALE
  [31:0] COUNT
0x3A030 cpsw3_CPSW_NU_CPSW_NU_STAT_RXOCTETS_k — Total number of received bytes in good frames
  [31:0] COUNT
0x3A034 cpsw3_CPSW_NU_CPSW_NU_STAT_TXGOODFRAMES_k — Total number of good frames transmitted
  [31:0] COUNT
0x3A038 cpsw3_CPSW_NU_CPSW_NU_STAT_TXBROADCASTFRAMES_k — Total number of good broadcast frames transmitted
  [31:0] COUNT
0x3A03C cpsw3_CPSW_NU_CPSW_NU_STAT_TXMULTICASTFRAMES_k — Total number of good multicast frames transmitted
  [31:0] COUNT
0x3A040 cpsw3_CPSW_NU_CPSW_NU_STAT_TXPAUSEFRAMES_k — Total number of pause frames transmitted
  [31:0] COUNT
0x3A044 cpsw3_CPSW_NU_CPSW_NU_STAT_TXDEFERREDFRAMES_k — Total number of deferred frames transmitted
  [31:0] COUNT
0x3A048 cpsw3_CPSW_NU_CPSW_NU_STAT_TXCOLLISIONFRAMES_k — Total number of transmitted frames experiencing a collision
  [31:0] COUNT
0x3A04C cpsw3_CPSW_NU_CPSW_NU_STAT_TXSINGLECOLLFRAMES_k — Total number of transmitted frames experiencing a single collision
  [31:0] COUNT
0x3A050 cpsw3_CPSW_NU_CPSW_NU_STAT_TXMULTCOLLFRAMES_k — Total number of transmitted frames experiencing multiple collisions
  [31:0] COUNT
0x3A054 cpsw3_CPSW_NU_CPSW_NU_STAT_TXEXCESSIVECOLLISIONS_k — Total number of transmitted frames abandoned due to excessive collisions
  [31:0] COUNT
0x3A058 cpsw3_CPSW_NU_CPSW_NU_STAT_TXLATECOLLISIONS_k — Total number of transmitted frames abandoned due to a late collision
  [31:0] COUNT
0x3A05C cpsw3_CPSW_NU_CPSW_NU_STAT_RXIPGERROR_k — Total number of receive inter-packet gap errors (10G only)
  [31:0] COUNT
0x3A060 cpsw3_CPSW_NU_CPSW_NU_STAT_TXCARRIERSENSEERRORS_k — Total number of transmitted frames that experienced a carrier loss
  [31:0] COUNT
0x3A064 cpsw3_CPSW_NU_CPSW_NU_STAT_TXOCTETS_k — Total number of bytes in all good frames transmitted
  [31:0] COUNT
0x3A068 cpsw3_CPSW_NU_CPSW_NU_STAT_OCTETFRAMES64_k — Total number of 64-byte frames received and transmitted
  [31:0] COUNT
0x3A06C cpsw3_CPSW_NU_CPSW_NU_STAT_OCTETFRAMES65T127_k — Total number of frames of size 65 to 127 bytes received and transmitted
  [31:0] COUNT
0x3A070 cpsw3_CPSW_NU_CPSW_NU_STAT_OCTETFRAMES128T255_k — Total number of frames of size 128 to 255 bytes received and transmitted
  [31:0] COUNT
0x3A074 cpsw3_CPSW_NU_CPSW_NU_STAT_OCTETFRAMES256T511_k — Total number of frames of size 256 to 511 bytes received and transmitted
  [31:0] COUNT
0x3A078 cpsw3_CPSW_NU_CPSW_NU_STAT_OCTETFRAMES512T1023_k — Total number of frames of size 512 to 1023 bytes received and transmitted
  [31:0] COUNT
0x3A07C cpsw3_CPSW_NU_CPSW_NU_STAT_OCTETFRAMES1024TUP_k — Total number of frames of size 1024 to rx_maxlen bytes received and 1024 bytes or greater transmitted
  [31:0] COUNT
0x3A080 cpsw3_CPSW_NU_CPSW_NU_STAT_NETOCTETS_k — Total number of bytes received and transmitted
  [31:0] COUNT
0x3A084 cpsw3_CPSW_NU_CPSW_NU_STAT_RX_BOTTOM_OF_FIFO_DROP_k — Receive Bottom of FIFO Drop
  [31:0] COUNT
0x3A088 cpsw3_CPSW_NU_CPSW_NU_STAT_PORTMASK_DROP_k — Total number of dropped frames received due to portmask
  [31:0] COUNT
0x3A08C cpsw3_CPSW_NU_CPSW_NU_STAT_RX_TOP_OF_FIFO_DROP_k — Receive Top of FIFO Drop
  [31:0] COUNT
0x3A090 cpsw3_CPSW_NU_CPSW_NU_STAT_ALE_RATE_LIMIT_DROP_k — Total number of dropped frames due to ALE Rate Limiting
  [31:0] COUNT
0x3A094 cpsw3_CPSW_NU_CPSW_NU_STAT_ALE_VID_INGRESS_DROP_k — Total number of dropped frames due to ALE VID Ingress
  [31:0] COUNT
0x3A098 cpsw3_CPSW_NU_CPSW_NU_STAT_ALE_DA_EQ_SA_DROP_k — Total number of dropped frames due to DA=SA
  [31:0] COUNT
0x3A09C cpsw3_CPSW_NU_CPSW_NU_STAT_ALE_BLOCK_DROP_k — Total number of dropped frames due to ALE Block Mode
  [31:0] COUNT
0x3A0A0 cpsw3_CPSW_NU_CPSW_NU_STAT_ALE_SECURE_DROP_k — Total number of dropped frames due to ALE Secure Mode
  [31:0] COUNT
0x3A0A4 cpsw3_CPSW_NU_CPSW_NU_STAT_ALE_AUTH_DROP_k — Total number of dropped frames due to ALE Authentication
  [31:0] COUNT
0x3A0A8 cpsw3_CPSW_NU_CPSW_NU_STAT_ALE_UNKN_UNI_k — ALE Receive Unknown Unicast
  [31:0] COUNT
0x3A0AC cpsw3_CPSW_NU_CPSW_NU_STAT_ALE_UNKN_UNI_BCNT_k — ALE Receive Unknown Unicast Bytecount
  [31:0] COUNT
0x3A0B0 cpsw3_CPSW_NU_CPSW_NU_STAT_ALE_UNKN_MLT_k — ALE Receive Unknown Multicast
  [31:0] COUNT
0x3A0B4 cpsw3_CPSW_NU_CPSW_NU_STAT_ALE_UNKN_MLT_BCNT_k — ALE Receive Unknown Multicast Bytecount
  [31:0] COUNT
0x3A0B8 cpsw3_CPSW_NU_CPSW_NU_STAT_ALE_UNKN_BRD_k — ALE Receive Unknown Broadcast
  [31:0] COUNT
0x3A0BC cpsw3_CPSW_NU_CPSW_NU_STAT_ALE_UNKN_BRD_BCNT_k — ALE Receive Unknown Broadcast Bytecount
  [31:0] COUNT
0x3A0C0 cpsw3_CPSW_NU_CPSW_NU_STAT_ALE_POL_MATCH_k — ALE Policer Matched
  [31:0] COUNT
0x3A0C4 cpsw3_CPSW_NU_CPSW_NU_STAT_ALE_POL_MATCH_RED_k — ALE Policer Matched and Condition Red
  [31:0] COUNT
0x3A0C8 cpsw3_CPSW_NU_CPSW_NU_STAT_ALE_POL_MATCH_YELLOW_k — ALE Policer Matched and Condition Yellow
  [31:0] COUNT
0x3A0CC cpsw3_CPSW_NU_CPSW_NU_STAT_ALE_MULT_SA_DROP_k — ALE Multicast Source Address Drop
  [31:0] COUNT — ALE Multicast Source Address drop
0x3A0D0 cpsw3_CPSW_NU_CPSW_NU_STAT_ALE_DUAL_VLAN_DROP_k — ALE Dual VLAN Drop
  [31:0] COUNT — ALE Dual VLAN drop
0x3A0D4 cpsw3_CPSW_NU_CPSW_NU_STAT_ALE_LEN_ERROR_DROP_k — ALE Length Error Drop
  [31:0] COUNT — ALE Length Error drop
0x3A0D8 cpsw3_CPSW_NU_CPSW_NU_STAT_ALE_IP_NEXT_HDR_DROP_k — ALE IP Next Header Drop
  [31:0] COUNT — ALE Next Header drop
0x3A0DC cpsw3_CPSW_NU_CPSW_NU_STAT_ALE_IPV4_FRAG_DROP_k — ALE IPV4 Frag Drop
  [31:0] COUNT — ALE IPV4 Fragment drop
0x3A140 cpsw3_CPSW_NU_CPSW_NU_STAT_IET_RX_ASSEMBLY_ERROR_REG_k — IET Receive Assembly Error
  [31:0] IET_RX_ASSEMBLY_ERROR
0x3A144 cpsw3_CPSW_NU_CPSW_NU_STAT_IET_RX_ASSEMBLY_OK_REG_k — IET Receive Assembly Ok
  [31:0] IET_RX_ASSEMBLY_OK
0x3A148 cpsw3_CPSW_NU_CPSW_NU_STAT_IET_RX_SMD_ERROR_REG_k — IET Receive Smd Error
  [31:0] IET_RX_SMD_ERROR
0x3A14C cpsw3_CPSW_NU_CPSW_NU_STAT_IET_RX_FRAG_REG_k — IET Receive Frag
  [31:0] IET_RX_FRAG
0x3A150 cpsw3_CPSW_NU_CPSW_NU_STAT_IET_TX_HOLD_REG_k — IET Transmit Hold
  [31:0] IET_TX_HOLD
0x3A154 cpsw3_CPSW_NU_CPSW_NU_STAT_IET_TX_FRAG_REG_k — IET Transmit Frag
  [31:0] IET_TX_FRAG
0x3A17C cpsw3_CPSW_NU_CPSW_NU_STAT_TX_MEMORY_PROTECT_ERROR_k — Transmit Memory Protect CRC Error
  [7:0] COUNT
0x3A180 cpsw3_CPSW_NU_CPSW_NU_STAT_ENET_PN_TX_PRI_REG_k_j — ENET Port n PRIORITY N Packet Count
  [31:0] PN_TX_PRIN — ENET TX Priority Packet Count
0x3A1A0 cpsw3_CPSW_NU_CPSW_NU_STAT_ENET_PN_TX_PRI_BCNT_REG_k_j — ENET Port n PRIORITY N Packet Byte Count
  [31:0] PN_TX_PRIN_BCNT
0x3A1C0 cpsw3_CPSW_NU_CPSW_NU_STAT_ENET_PN_TX_PRI_DROP_REG_k_j — ENET Port n PRIORITY N Packet Drop Count
  [31:0] PN_TX_PRIN_DROP
0x3A1E0 cpsw3_CPSW_NU_CPSW_NU_STAT_ENET_PN_TX_PRI_DROP_BCNT_REG_k_j — ENET Port n PRIORITY N Packet Drop Byte Count
  [31:0] PN_TX_PRIN_DROP_BCNT
0x3D000 cpsw3_CPSW_NU_CPTS access not given reset not defined
0x3D000 cpsw3_IDVER_REG ro reset 0x4E8A010C — Identification and Version Register
  [31:16] TX_IDENT — Identification value
  [15:11] RTL_VER — RTL version value
  [10:8] MAJOR_VER — Major version value
  [7:0] MINOR_VER — Minor version value
0x3D004 cpsw3_CPSW_NU_CPTS_CONTROL_REG reset 0x4 — Time Sync Control Register
  [31:28] TS_SYNC_SEL — TS_SYNC output time stamp counter bit select. 0h TS_SYNC disabled.1h-Fh TS_SYNC is time stamp counter bits 31 (Fh) down to 17 (1h).
  [17] TS_GENF_CLR_EN — GENF (and ESTF) Clear Enable. 0h A CPTS_GENFn output is not cleared when the associated CPSW_GENF_LENGTH_REG_l[31:0] is cleared to zero.1h A CPTS_GENFn output is cleared when the associated CPSW_GENF_LENGTH_REG_l[31:0] is cleared to zero.
  [16] TS_RX_NO_EVENT — Timestamp Ethernet Receive produces no events. 0h Ethernet receive timesync events enabled.1h Ethernet receive timesync events disabled.
  [n+7] HW{n}_TS_PUSH_EN (n=1..8) — Hardware push {n} enable.
  [7] TS_PPM_DIR — PPM Correction Direction. 0h Increase the TIME_STAMP[63:0] value (CPSW_CPTS_EVENT_0_REG and CPSW_CPTS_EVENT_3_REG) by the PPM value.1h Decrease the TIME_STAMP[63:0] value (CPSW_CPTS_EVENT_0_REG and CPSW_CPTS_EVENT_3_REG and) by the PPM value.
  [6] TS_COMP_TOG — Time Stamp Compare Toggle mode. 0h TS_COMP is in non-toggle mode.1h TS_COMP is in toggle mode.
  [5] MODE — 64-Bit Mode. 0h The time stamp is 32-bits with the upper 32-bits forced to zero.1h The time stamp is 64-bits.
  [4] SEQUENCE_EN — Sequence Enable. 0h The time stamp value increments with the selected RFTCLK1h The time stamp for received packets is the sequence number of the received packet (first packet is 1, second packet is 2, etc).
  [3] TSTAMP_EN — Host Receive Time Stamp Enable. 0h Time stamps are disabled on received packets to host.1h Time stamps enabled on received packets to host (PCIE_CPTS_CONTROL_REG[0] CPTS_EN must be set).
  [2] TS_COMP_POLARITY — TS_COMP Polarity. 0h TS_COMP is asserted low.1h TS_COMP is asserted high.
  [1] INT_TEST — Interrupt Test. When set, this bit allows the raw interrupt to be written to facilitate interrupt test.
  [0] CPTS_EN — Time Sync Enable. When disabled (cleared to zero), the RCLK domain is held in reset.
0x3D008 cpsw3_CPSW_NU_CPTS_RFTCLK_SEL_REG — RFTCLK Select Register
  [4:0] RFTCLK_SEL — Reference clock select. This bit field is used to control an external multiplexer that selects one out of 8 clocks for time sync reference. 0h Selects CPSWHSDIV_CLKOUT2 clock1h Selects MAINHSDIV_CLKOUT3 clock2h Selects MCU_CPTS0_RFT_CLK I/O pin3h Selects CPTS0_RFT_CLK I/O pin4h Selects MCU_EXT_REFCLK0 I/O pin5h Selects EXT_REFCLK1 I/O pin6h Selects PCIE0_TXI0_CLK clock7h Selects PCIE1_TXI0_CLK clock The RFTCLK_SEL value can be written only when the [0] CPTS_EN and [3] TSTAMP_EN bits are cleared to zero in the CPSW_CPTS_CONTROL_REG register.
0x3D00C cpsw3_CPSW_NU_CPTS_TS_PUSH_REG wo — Time Stamp Event Push Register
  [0] TS_PUSH — Time stamp event push. When a logic high is written to this bit a time stamp event is pushed onto the event FIFO. The time stamp value is the time of the write of this register, not the time of the event read. The time stamp value can then be read on interrupt via the event registers. Software should not push a second time stamp event onto the event FIFO until the first time stamp value has been read from the event FIFO (there should be only one time stamp event in the event FIFO at any given time). This bit is write only and always reads zero.
0x3D010 cpsw3_TS_LOAD_VAL_REG — Time Stamp Load Low Value Register
  [31:0] TS_LOAD_VAL — Time stamp load low value
0x3D014 cpsw3_CPSW_NU_CPTS_TS_LOAD_EN_REG wo — Time Stamp Load Enable Register
  [0] TS_LOAD_EN — Time Stamp Load Enable. Writing a one to this bit enables the time stamp value to be written with the value in CPSW_CPTS_TS_LOAD_VAL_REG/ CPSW_CPTS_TS_LOAD_HIGH_VAL_REG. This bit is write only and will be cleared by the hardware after one clock. The upper 32-bits of the time stamp (CPSW_CPTS_TS_LOAD_HIGH_VAL_REG) are forced to zero in 32-bit mode.
0x3D018 cpsw3_TS_COMP_VAL_REG — Time Stamp Comparison Low Value Register
  [31:0] TS_COMP_VAL — Time Stamp Comparison Low Value. Writing a non-zero value to the CPSW_CPTS_TS_COMP_LEN_REG[31-0] TS_COMP_LENGTH register causes a pulse of TS_COMP_LENGTH RCLK periods on the TS_COMP output and a comparison event when the TIME_STAMP counter value is equivalent to CPSW_CPTS_TS_COMP_VAL_REG[31-0] TS_COMP_VAL.
0x3D01C cpsw3_CPSW_NU_CPTS_TS_COMP_LEN_REG — Time Stamp Comparison Length Register
  [31:0] TS_COMP_LENGTH — Time Stamp Comparison Length. Writing a non-zero value to this field enables the time stamp comparison event and output. This value should be zero when the CPSW_GENF_COMP_LOW_REG_L[31-0] COMP_LOW and CPSW_GENF_COMP_HIGH_REG_L[31-0] COMP_HIGH registers are written.
0x3D020 cpsw3_CPSW_NU_CPTS_INTSTAT_RAW_REG — Interrupt Status Register Raw
  [0] TS_PEND_RAW — TS_PEND_RAW int read (before enable). Writable when CPSW_CPTS_CONTROL_REG[1] INT_TEST = 1h A one in this bit indicates that there are one or more events in the event FIFO.
0x3D024 cpsw3_CPSW_NU_CPTS_INTSTAT_MASKED_REG ro — Interrupt Status Register Masked
  [0] TS_PEND — TS_PEND masked interrupt read (after enable)
0x3D028 cpsw3_CPSW_NU_CPTS_INT_ENABLE_REG — Interrupt Enable Register
  [0] TS_PEND_EN — TS_PEND masked interrupt enable
0x3D02C cpsw3_CPSW_NU_CPTS_TS_COMP_NUDGE_REG — Time Stamp Comparison Nudge Register
  [7:0] NUDGE — Time stamp Comparison Nudge Value. This two's complement number is added to the CPSW_CPTS_TS_COMP_LEN_REG[31-0] TS_COMP_LENGTH value to increase or decrease the TS_COMP length by the CPSW_CPTS_TS_COMP_NUDGE_REG[7-0] NUDGE amount. Only a single high or low time is adjusted and the CPSW_CPTS_TS_COMP_NUDGE_REG value is cleared to zero when the nudge has occurred.
0x3D030 cpsw3_CPSW_NU_CPTS_EVENT_POP_REG wo — Event Pop Register
  [0] EVENT_POP — Event Pop. When a logic high is written to this bit an event is popped off the event FIFO. The event FIFO pop occurs as part of the interrupt process after the event has been read from the CPSW_CPTS_EVENT_0_REG to CPSW_CPTS_EVENT_3_REG registers. Popping an event discards the event and causes the next event, if any, to be moved to the top of the FIFO ready to be read by software on interrupt.
0x3D034 cpsw3_CPSW_NU_CPTS_EVENT_0_REG ro — Event 0 Register
  [31:0] TIME_STAMP — Time Stamp. The time stamp is valid for transmit, receive, and time stamp push event types. The time stamp value is not valid for counter roll event types.
0x3D038 cpsw3_CPSW_NU_CPTS_EVENT_1_REG ro — Event 1 Register
  [29] PREMPT_QUEUE
  [28:24] PORT_NUMBER — Port Number. Indicates the port number (encoded) of an Ethernet event or the encoded hardware time stamp number.
  [23:20] EVENT_TYPE — Time Sync Event Type 0h Time Stamp Push Event1h Time Stamp Rollover Event2h Time Stamp Half Rollover Event3h Hardware Time Stamp Push Event4h Ethernet Receive Event5h Ethernet Transmit Event6h Time Stamp Compare Event7h Host Transmit Event8h-Fh Reserved
  [19:16] MESSAGE_TYPE — Message type. The message type value that was contained in an Ethernet transmit or receive time sync packet. This field is valid only for Ethernet transmit or receive events.
  [15:0] SEQUENCE_ID — Sequence ID. The 16-bit sequence id is the value that was contained in an Ethernet transmit or receive time sync packet. This field is valid only for Ethernet transmit or receive events.
0x3D03C cpsw3_CPSW_NU_CPTS_EVENT_2_REG ro — Event 2 Register
  [7:0] DOMAIN — Domain. The 8-bit domain is the value that was contained in an Ethernet transmit or receive time sync packet. This field is valid only for Ethernet transmit or receive events.
0x3D040 cpsw3_CPSW_NU_CPTS_EVENT_3_REG ro — Event 3 Register
  [31:0] TIME_STAMP — Time Stamp. The time stamp upper 32-bits are valid for transmit, receive, and time stamp push event types. This value is zero in 32-bit mode.
0x3D044 cpsw3_CPSW_NU_CPTS_TS_LOAD_HIGH_VAL_REG — Time Stamp Load High Value Register
  [31:0] TS_LOAD_VAL — Time Stamp Load high Value. Writing the CPSW_CPTS_TS_LOAD_EN_REG[0] TS_LOAD_EN bit causes the value contained in this register to be written into the time stamp. The time stamp value is read by initiating a time stamp push event, not by reading this register. When reading this register, the value read is not the time stamp, but is the value that was last written to this register. This value is unused in 32-bit mode
0x3D048 cpsw3_CPSW_NU_CPTS_TS_COMP_HIGH_VAL_REG — Time Stamp Comparison High Value Register
  [31:0] TS_COMP_HIGH_VAL — Time Stamp Comparison High Value. Writing a non-zero value to the CPSW_CPTS_TS_COMP_LEN_REG[31-0] TS_COMP_LENGTH register causes a pulse of TS_COMP_LENGTH RCLK periods on the TS_COMP output and a comparison event when the [31-0]TIME_STAMP counter value is equivalent to CPSW_CPTS_TS_COMP_VAL_REG[31-0] TS_COMP_VAL and CPSW_CPTS_TS_COMP_HIGH_VAL_REG[31-0] TS_COMP_HIGH_VAL. This value is unused in 32-bit mode. The upper 32-bits in CPSW_CPTS_TS_COMP_HIGH_VAL_REG register should be written before the lower 32-bits in the CPSW_CPTS_TS_COMP_VAL_REG register.
0x3D04C cpsw3_CPSW_NU_CPTS_TS_ADD_VAL_REG — TS Add Value Register
  [2:0] ADD_VAL — The ts_add_value[2:0] is added to 1 to comprise the time stamp increment value. The time stamp increment value is added to the current time stamp (time_stamp[63:0]) on each RCLK. The time stamp increment value can be adjusted by nudge and ppm also. The CPSW_CPTS_TS_ADD_VAL_REG[2-0] ADD_VAL value may be non-zero in 64-bit mode only.
0x3D050 cpsw3_CPSW_NU_CPTS_TS_PPM_LOW_VAL_REG — Time Stamp PPM Low Value Register
  [31:0] TS_PPM_LOW_VAL — Time Stamp PPM Low Value. The 64-bit PPM value takes effect when this low value is written. The high value should be written first. Note: There should be at least 10 clocks in between writes to the low register to ensure that the previous operation has been seen.
0x3D054 cpsw3_CPSW_NU_CPTS_TS_PPM_HIGH_VAL_REG — Time Stamp PPM High Value Register
  [9:0] TS_PPM_HIGH_VAL — Time Stamp PPM High Value. This value should be written first (before the low value is written). The minimum value of the Time Stamp PPM is 0x400 (all 42 bits: CPSW_CPTS_TS_PPM_LOW_VAL_REG[31-0] TS_PPM_LOW_VAL and CPSW_CPTS_TS_PPM_HIGH_VAL_REG[9-0] TS_PPM_HIGH_VAL).
0x3D058 cpsw3_CPSW_NU_CPTS_TS_NUDGE_VAL_REG — Time Stamp Nudge Value Register
  [7:0] TS_NUDGE_VAL — Time stamp Nudge Value. This two's complement number is added to the CPSW_CPTS_EVENT_0_REG[31-0] TIME_STAMP and CPSW_CPTS_EVENT_3_REG[[31-0] TIME_STAMP value to increase or decrease the time stamp value by the CPSW_CPTS_TS_NUDGE_VAL_REG[7-0] TS_NUDGE_VAL amount. The TS_NUDGE_VAL value is cleared to zero when the nudge has occurred. The minimum value of the Time Stamp PPM is 0x400 (all 42 bits: CPSW_CPTS_TS_PPM_LOW_VAL_REG[31-0] TS_PPM_LOW_VAL and CPSW_CPTS_TS_PPM_HIGH_VAL_REG[9-0] TS_PPM_HIGH_VAL).
0x3D0D0 cpsw3_CPSW_NU_CPTS_TS_CONFIG ro reset 0x2002 — Time Stamp Configuration Read
  [15:8] EVNT_FIFO_DEPTH — The Event FIFO Depth
  [7:0] NUM_GENF — The number of CPTS GENF outputs
